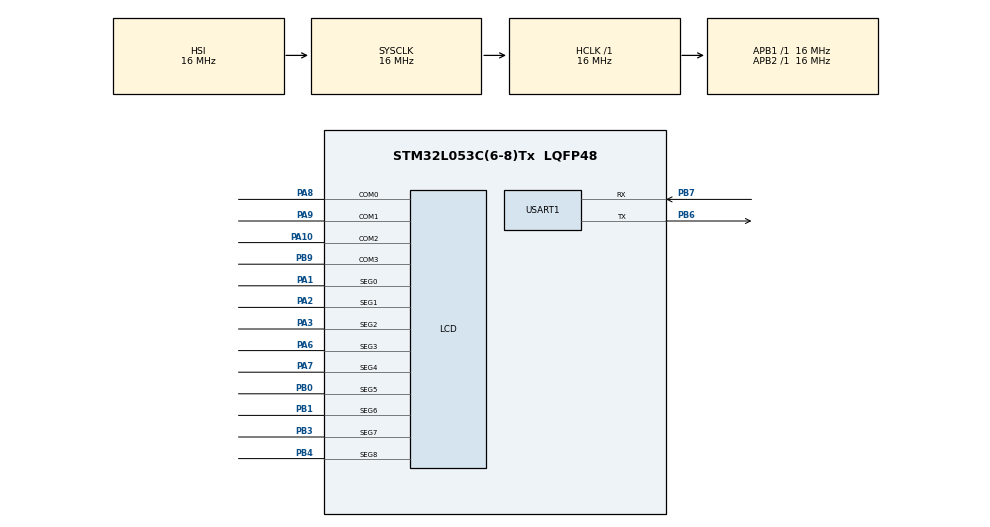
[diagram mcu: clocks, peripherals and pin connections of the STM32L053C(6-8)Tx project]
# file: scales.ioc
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LCD.Contrast=LCD_CONTRASTLEVEL_5
LCD.DeadTime=LCD_DEADTIME_0
LCD.Divider=LCD_DIVIDER_21
LCD.HighDrive=LCD_HIGHDRIVE_1
LCD.Prescaler=LCD_PRESCALER_8
LCD.PulseOnDuration=LCD_PULSEONDURATION_1
Mcu.Family=STM32L0
Mcu.Name=STM32L053C(6-8)Tx
Mcu.Package=LQFP48
PA1.Mode=SEG0
PA1.Signal=LCD_SEG0
PA10.Mode=1/4 Duty Cycle
PA10.Signal=LCD_COM2
PA13.Mode=Serial_Wire
PA13.Signal=SYS_SWDIO
PA14.Mode=Serial_Wire
PA14.Signal=SYS_SWCLK
PA2.Mode=SEG1
PA2.Signal=LCD_SEG1
PA3.Mode=SEG2
PA3.Signal=LCD_SEG2
PA6.Mode=SEG3
PA6.Signal=LCD_SEG3
PA7.Mode=SEG4
PA7.Signal=LCD_SEG4
PA8.Mode=1/4 Duty Cycle
PA8.Signal=LCD_COM0
PA9.Mode=1/4 Duty Cycle
PA9.Signal=LCD_COM1
PB0.Mode=SEG5
PB0.Signal=LCD_SEG5
PB1.Mode=SEG6
PB1.Signal=LCD_SEG6
PB3.Mode=SEG7
PB3.Signal=LCD_SEG7
PB4.Mode=SEG8
PB4.Signal=LCD_SEG8
PB6.Mode=Asynchronous
PB6.Signal=USART1_TX
PB7.Mode=Asynchronous
PB7.Signal=USART1_RX
PB9.Mode=1/4 Duty Cycle
PB9.Signal=LCD_COM3
ProjectManager.HeapSize=0x200
ProjectManager.StackSize=0x400
ProjectManager.TargetToolchain=SW4STM32
RCC.AHBFreq_Value=16000000
RCC.APB1Freq_Value=16000000
RCC.APB1TimFreq_Value=16000000
RCC.APB2Freq_Value=16000000
RCC.APB2TimFreq_Value=16000000
RCC.HCLKFreq_Value=16000000
RCC.HSE_VALUE=8000000
RCC.HSI16_VALUE=16000000
RCC.HSI48_VALUE=48000000
RCC.HSI_VALUE=16000000
RCC.LSE_VALUE=32768
RCC.MSI_VALUE=2097000
RCC.SYSCLKFreq_VALUE=16000000
RCC.SYSCLKSource=RCC_SYSCLKSOURCE_HSI
RCC.Usart1ClockSelection=RCC_USART1CLKSOURCE_SYSCLK
RCC.VCOOutputFreq_Value=48000000
USART1.VirtualMode-Asynchronous=VM_ASYNC
USART1.WordLength=WORDLENGTH_8B
VP_LCD_LCD_Bias.Mode=1/3 Bias
board=scales

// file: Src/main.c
/**
  ******************************************************************************
  * File Name          : main.c
  * Description        : Main program body
  ******************************************************************************
  ** This notice applies to any and all portions of this file
  * that are not between comment pairs USER CODE BEGIN and
  * USER CODE END. Other portions of this file, whether
  * inserted by the user or by software development tools
  * are owned by their respective copyright owners.
  *
  * COPYRIGHT(c) 2017 STMicroelectronics
  *
  * Redistribution and use in source and binary forms, with or without modification,
  * are permitted provided that the following conditions are met:
  *   1. Redistributions of source code must retain the above copyright notice,
  *      this list of conditions and the following disclaimer.
  *   2. Redistributions in binary form must reproduce the above copyright notice,
  *      this list of conditions and the following disclaimer in the documentation
  *      and/or other materials provided with the distribution.
  *   3. Neither the name of STMicroelectronics nor the names of its contributors
  *      may be used to endorse or promote products derived from this software
  *      without specific prior written permission.
  *
  * THIS SOFTWARE IS PROVIDED BY THE COPYRIGHT HOLDERS AND CONTRIBUTORS "AS IS"
  * AND ANY EXPRESS OR IMPLIED WARRANTIES, INCLUDING, BUT NOT LIMITED TO, THE
  * IMPLIED WARRANTIES OF MERCHANTABILITY AND FITNESS FOR A PARTICULAR PURPOSE ARE
  * DISCLAIMED. IN NO EVENT SHALL THE COPYRIGHT HOLDER OR CONTRIBUTORS BE LIABLE
  * FOR ANY DIRECT, INDIRECT, INCIDENTAL, SPECIAL, EXEMPLARY, OR CONSEQUENTIAL
  * DAMAGES (INCLUDING, BUT NOT LIMITED TO, PROCUREMENT OF SUBSTITUTE GOODS OR
  * SERVICES; LOSS OF USE, DATA, OR PROFITS; OR BUSINESS INTERRUPTION) HOWEVER
  * CAUSED AND ON ANY THEORY OF LIABILITY, WHETHER IN CONTRACT, STRICT LIABILITY,
  * OR TORT (INCLUDING NEGLIGENCE OR OTHERWISE) ARISING IN ANY WAY OUT OF THE USE
  * OF THIS SOFTWARE, EVEN IF ADVISED OF THE POSSIBILITY OF SUCH DAMAGE.
  *
  ******************************************************************************
  */

#include "main.h"
#include "stm32l0xx_hal.h"
#include "lcd.h"
#include "usart.h"
#include "gpio.h"

/* USER CODE BEGIN Includes */
#include "screen.h"

/* USER CODE END Includes */

/* USER CODE BEGIN PV */
/* Private variables ---------------------------------------------------------*/

/* USER CODE END PV */

void SystemClock_Config(void);

/* USER CODE BEGIN PFP */
/* Private function prototypes -----------------------------------------------*/

/* USER CODE END PFP */

int main(void)
{

  /* MCU Configuration----------------------------------------------------------*/

  /* Reset of all peripherals, Initializes the Flash interface and the Systick. */
  HAL_Init();

  /* Configure the system clock */
  SystemClock_Config();

  /* Initialize all configured peripherals */
  MX_GPIO_Init();
  MX_USART1_UART_Init();
  MX_LCD_Init();

  /* USER CODE BEGIN 2 */
  HAL_LCD_MspInit(&hlcd);
//HAL_Delay(10);
//  LCD->RAM[LCD_RAM_REGISTER0] = 0xFFFFFFFF;
//  LCD->RAM[LCD_RAM_REGISTER2] = 0xFFFFFFFF;
//  LCD->RAM[LCD_RAM_REGISTER4] = 0xFFFFFFFF;
//  LCD->RAM[LCD_RAM_REGISTER6] = 0xFFFFFFFF;
//HAL_LCD_UpdateDisplayRequest(&hlcd);

  //LCD->RAM[LCD_RAM_REGISTER0] = LCD_PIN_4; // COM0
//  LCD->RAM[LCD_RAM_REGISTER2] = LCD_PIN_5; // COM1
//  LCD->RAM[LCD_RAM_REGISTER4] = LCD_PIN_5; // COM2
  //LCD->RAM[LCD_RAM_REGISTER6] = LCD_SEG_4; // COM3

  //HAL_LCD_UpdateDisplayRequest(&hlcd);

   //Screen_Update(&hlcd, 10, 10, 10, 10);

    //int count = 0;
    uint8_t hundreds = 10;
    uint8_t tens = 10;
    uint8_t ones = 10;
    uint8_t decimal = 0;

   //Screen_Update(&hlcd, hundreds, tens, ones, decimal);

   Screen_Update(&hlcd, 8, 8, 8, 2);

  /* USER CODE END 2 */

  /* Infinite loop */
  while (1)
  {

  /* USER CODE BEGIN 3 */
//      HAL_Delay(1000);
//
//      decimal++;
//      if (decimal > 9) {
//          decimal = 0;
//          if (ones == 10) {
//              ones = 1;
//          } else {
//              ones++;
//          }
//          if (ones > 9) {
//              ones = 0;
//              if (tens == 10) {
//                  tens = 1;
//              } else {
//                  tens++;
//              }
//              if (tens > 9) {
//                  tens = 0;
//                  if (hundreds == 10) {
//                      hundreds = 1;
//                  } else {
//                      hundreds++;
//                  }
//                  if (hundreds > 9) {
//                      hundreds = 10;
//                      tens = 10;
//                      ones = 10;
//                      decimal = 0;
//                  }
//              }
//          }
//      }
//
//      Screen_Update(&hlcd, hundreds, tens, ones, decimal);
  }
  /* USER CODE END 3 */

}

/** System Clock Configuration
*/
void SystemClock_Config(void)
{

  RCC_OscInitTypeDef RCC_OscInitStruct;
  RCC_ClkInitTypeDef RCC_ClkInitStruct;
  RCC_PeriphCLKInitTypeDef PeriphClkInit;

    /**Configure the main internal regulator output voltage
    */
  __HAL_PWR_VOLTAGESCALING_CONFIG(PWR_REGULATOR_VOLTAGE_SCALE1);

    /**Initializes the CPU, AHB and APB busses clocks
    */
  RCC_OscInitStruct.OscillatorType = RCC_OSCILLATORTYPE_HSI|RCC_OSCILLATORTYPE_LSI;
  RCC_OscInitStruct.HSIState = RCC_HSI_ON;
  RCC_OscInitStruct.HSICalibrationValue = 16;
  RCC_OscInitStruct.LSIState = RCC_LSI_ON;
  RCC_OscInitStruct.PLL.PLLState = RCC_PLL_NONE;
  if (HAL_RCC_OscConfig(&RCC_OscInitStruct) != HAL_OK)
  {
    _Error_Handler(__FILE__, __LINE__);
  }

    /**Initializes the CPU, AHB and APB busses clocks
    */
  RCC_ClkInitStruct.ClockType = RCC_CLOCKTYPE_HCLK|RCC_CLOCKTYPE_SYSCLK
                              |RCC_CLOCKTYPE_PCLK1|RCC_CLOCKTYPE_PCLK2;
  RCC_ClkInitStruct.SYSCLKSource = RCC_SYSCLKSOURCE_HSI;
  RCC_ClkInitStruct.AHBCLKDivider = RCC_SYSCLK_DIV1;
  RCC_ClkInitStruct.APB1CLKDivider = RCC_HCLK_DIV1;
  RCC_ClkInitStruct.APB2CLKDivider = RCC_HCLK_DIV1;

  if (HAL_RCC_ClockConfig(&RCC_ClkInitStruct, FLASH_LATENCY_0) != HAL_OK)
  {
    _Error_Handler(__FILE__, __LINE__);
  }

  PeriphClkInit.PeriphClockSelection = RCC_PERIPHCLK_USART1|RCC_PERIPHCLK_RTC;
  PeriphClkInit.Usart1ClockSelection = RCC_USART1CLKSOURCE_SYSCLK;
  PeriphClkInit.RTCClockSelection = RCC_RTCCLKSOURCE_LSI;
  if (HAL_RCCEx_PeriphCLKConfig(&PeriphClkInit) != HAL_OK)
  {
    _Error_Handler(__FILE__, __LINE__);
  }

    /**Configure the Systick interrupt time
    */
  HAL_SYSTICK_Config(HAL_RCC_GetHCLKFreq()/1000);

    /**Configure the Systick
    */
  HAL_SYSTICK_CLKSourceConfig(SYSTICK_CLKSOURCE_HCLK);

  /* SysTick_IRQn interrupt configuration */
  HAL_NVIC_SetPriority(SysTick_IRQn, 0, 0);
}

void _Error_Handler(char * file, int line)
{
  while(1)
  {
  }
}

/************************ (C) COPYRIGHT STMicroelectronics *****END OF FILE****/
